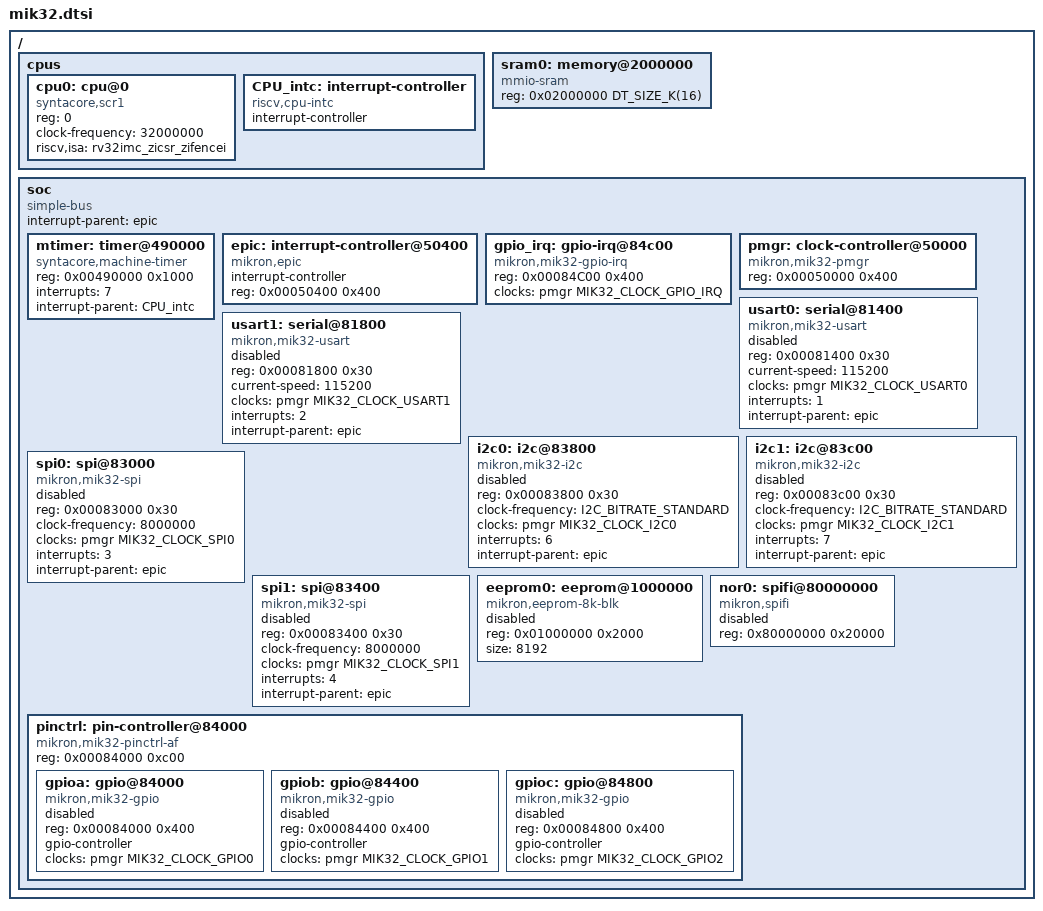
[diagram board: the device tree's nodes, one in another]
/*
 * Copyright (C) 2024
 * SPDX-License-Identifier: Apache-2.0
 */

#include <mem.h>
#include <zephyr/dt-bindings/gpio/gpio.h>
#include <mikron/mik32/mik32v2.h>
#include <zephyr/dt-bindings/clock/mik32-clocks.h>
#include <zephyr/dt-bindings/i2c/i2c.h>

/dts-v1/;

/ {
	#address-cells = <1>;
	#size-cells = <1>;
	cpus {
		#address-cells = <1>;
		#size-cells = <0>;
		cpu0: cpu@0 {
			reg = <0>;
			clock-frequency = <32000000>;
			compatible ="syntacore,scr1", "riscv";
			riscv,isa = "rv32imc_zicsr_zifencei";
		};

		CPU_intc: interrupt-controller {
			#address-cells = <0>;
			#interrupt-cells = <1>;
			interrupt-controller;
			compatible = "riscv,cpu-intc";
		};
	};

	sram0: memory@2000000 {
		compatible = "mmio-sram";
		reg = <0x02000000 DT_SIZE_K(16)>;
	};

	soc {
		#address-cells = <1>;
		#size-cells = <1>;
		compatible = "simple-bus";
		interrupt-parent = <&epic>;
		ranges;

		mtimer: timer@490000 {
			compatible = "syntacore,machine-timer";
			reg = <0x00490000 0x1000>;
			interrupts = <7>;
			interrupt-parent = < &CPU_intc >;
			status = "okay";
		};

		epic: interrupt-controller@50400 {
			compatible = "mikron,epic";
			#address-cells = <0>;
			#interrupt-cells = <1>;
			interrupt-controller;

			reg = <0x00050400 0x400>;
			status = "okay";
		};

		gpio_irq: gpio-irq@84c00 {
			compatible = "mikron,mik32-gpio-irq";
			reg = <0x00084C00 0x400>;
			clocks = <&pmgr MIK32_CLOCK_GPIO_IRQ>;
			status = "okay";
		};

		pmgr: clock-controller@50000 {
			compatible = "mikron,mik32-pmgr";
			reg = <0x00050000 0x400>;
			#clock-cells = <1>;
			status = "okay";
		};

		usart0: serial@81400 {
			compatible = "mikron,mik32-usart";
			reg = <0x00081400 0x30>;
			current-speed = <115200>;
			clocks = <&pmgr MIK32_CLOCK_USART0>;
			status = "disabled";

			interrupts = <1>;
			interrupt-parent = < &epic >;
		};

		usart1: serial@81800 {
			compatible = "mikron,mik32-usart";
			reg = <0x00081800 0x30>;
			current-speed = <115200>;
			clocks = <&pmgr MIK32_CLOCK_USART1>;
			status = "disabled";

			interrupts = <2>;
			interrupt-parent = < &epic >;
		};

		i2c0: i2c@83800 {
			compatible = "mikron,mik32-i2c";
			reg = <0x00083800 0x30>;
			#address-cells = <1>;
			#size-cells = <0>;
			clock-frequency = <I2C_BITRATE_STANDARD>;
			clocks = <&pmgr MIK32_CLOCK_I2C0>;
			status = "disabled";

			interrupts = <6>;
			interrupt-parent = < &epic >;
		};

		i2c1: i2c@83c00 {
			compatible = "mikron,mik32-i2c";
			reg = <0x00083c00 0x30>;
			#address-cells = <1>;
			#size-cells = <0>;
			clock-frequency = <I2C_BITRATE_STANDARD>;
			clocks = <&pmgr MIK32_CLOCK_I2C1>;
			status = "disabled";

			interrupts = <7>;
			interrupt-parent = < &epic >;
		};

		spi0: spi@83000 {
			compatible = "mikron,mik32-spi";
			reg = <0x00083000 0x30>;
			clock-frequency = <8000000>;
			clocks = <&pmgr MIK32_CLOCK_SPI0>;
			status = "disabled";

			interrupts = <3>;
			interrupt-parent = < &epic >;
		};

		spi1: spi@83400 {
			compatible = "mikron,mik32-spi";
			reg = <0x00083400 0x30>;
			clock-frequency = <8000000>;
			clocks = <&pmgr MIK32_CLOCK_SPI1>;
			status = "disabled";

			interrupts = <4>;
			interrupt-parent = < &epic >;
		};

		eeprom0: eeprom@1000000 {
			compatible = "mikron,eeprom-8k-blk";
			reg = <0x01000000 0x2000>;
			size = <8192>;
			status = "disabled";
		};

		nor0: spifi@80000000 {
			compatible = "mikron,spifi";
			reg = <0x80000000 0x20000>;
			status = "disabled";
		};

		pinctrl: pin-controller@84000 {
			compatible = "mikron,mik32-pinctrl-af";
			reg = <0x00084000 0xc00>;
			#address-cells = <1>;
			#size-cells = <1>;
			status = "okay";

			gpioa: gpio@84000 {
				compatible = "mikron,mik32-gpio";
				reg = <0x00084000 0x400>;
				gpio-controller;
				#gpio-cells = <2>;
				clocks = <&pmgr MIK32_CLOCK_GPIO0>;
				status = "disabled";
			};

			gpiob: gpio@84400 {
				compatible = "mikron,mik32-gpio";
				reg = <0x00084400 0x400>;
				gpio-controller;
				#gpio-cells = <2>;
				clocks = <&pmgr MIK32_CLOCK_GPIO1>;
				status = "disabled";
			};

			gpioc: gpio@84800 {
				compatible = "mikron,mik32-gpio";
				reg = <0x00084800 0x400>;
				gpio-controller;
				#gpio-cells = <2>;
				clocks = <&pmgr MIK32_CLOCK_GPIO2>;
				status = "disabled";
			};
		};
	};
};
